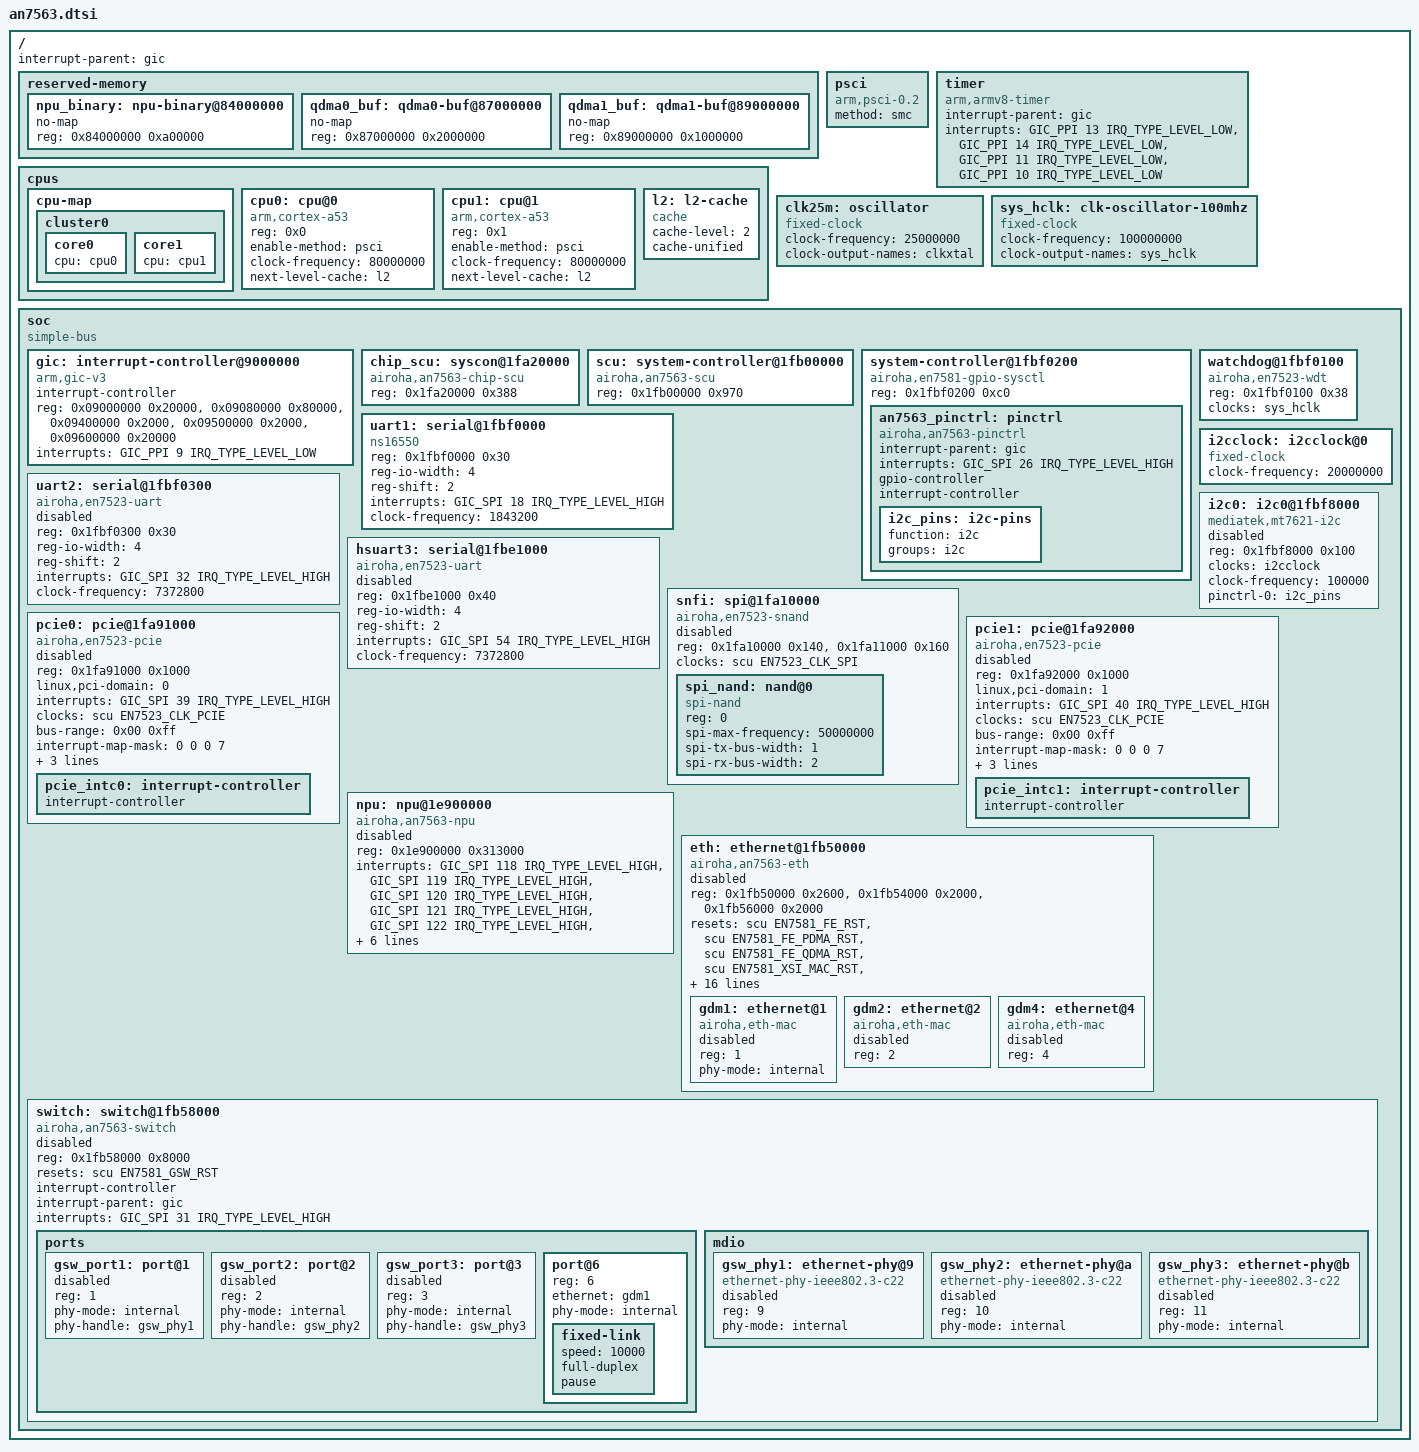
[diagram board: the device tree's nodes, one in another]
// SPDX-License-Identifier: (GPL-2.0-only OR BSD-2-Clause)
/*
 * Airoha AN7563 / AN7552 SoC dtsi.
 *
 * AN7563 boots a dual Cortex-A53 cluster in 32-bit AArch32 mode, but
 * its chip-SCU and SCU register windows match the EN7581 layout (the
 * IOMUX_1 register sits at chip-SCU offset 0x214, not 0x210 as on
 * EN7523). To share clk-en7523 / reset / pinctrl-airoha driver paths
 * with EN7581, the SCU nodes carry an AN7563-specific compatible
 * followed by the "airoha,en7581-{chip-,}scu" fallback compatible.
 */

#include <dt-bindings/interrupt-controller/irq.h>
#include <dt-bindings/interrupt-controller/arm-gic.h>
#include <dt-bindings/clock/en7523-clk.h>
#include <dt-bindings/reset/airoha,en7581-reset.h>
#include <dt-bindings/leds/common.h>

/ {
	interrupt-parent = <&gic>;
	#address-cells = <1>;
	#size-cells = <1>;

	/*
	 * TODO: offsets/sizes below follow the AN7581 pattern and are NOT
	 * yet confirmed against a live BE5000 (no /proc/iomem dump for
	 * this region available at time of writing). Verify before
	 * upstreaming.
	 */
	reserved-memory {
		#address-cells = <1>;
		#size-cells = <1>;
		ranges;

		npu_binary: npu-binary@84000000 {
			no-map;
			reg = <0x84000000 0xa00000>;
		};

		qdma0_buf: qdma0-buf@87000000 {
			no-map;
			reg = <0x87000000 0x2000000>;
		};

		qdma1_buf: qdma1-buf@89000000 {
			no-map;
			reg = <0x89000000 0x1000000>;
		};
	};

	psci {
		compatible = "arm,psci-0.2";
		method = "smc";
	};

	cpus {
		#address-cells = <1>;
		#size-cells = <0>;

		cpu-map {
			cluster0 {
				core0 {
					cpu = <&cpu0>;
				};

				core1 {
					cpu = <&cpu1>;
				};
			};
		};

		cpu0: cpu@0 {
			device_type = "cpu";
			compatible = "arm,cortex-a53";
			reg = <0x0>;
			enable-method = "psci";
			clock-frequency = <80000000>;
			next-level-cache = <&l2>;
		};

		cpu1: cpu@1 {
			device_type = "cpu";
			compatible = "arm,cortex-a53";
			reg = <0x1>;
			enable-method = "psci";
			clock-frequency = <80000000>;
			next-level-cache = <&l2>;
		};

		l2: l2-cache {
			compatible = "cache";
			cache-level = <2>;
			cache-unified;
		};
	};

	timer {
		compatible = "arm,armv8-timer";
		interrupt-parent = <&gic>;
		interrupts = <GIC_PPI 13 IRQ_TYPE_LEVEL_LOW>,
			     <GIC_PPI 14 IRQ_TYPE_LEVEL_LOW>,
			     <GIC_PPI 11 IRQ_TYPE_LEVEL_LOW>,
			     <GIC_PPI 10 IRQ_TYPE_LEVEL_LOW>;
	};

	clk25m: oscillator {
		compatible = "fixed-clock";
		#clock-cells = <0>;
		clock-frequency = <25000000>;
		clock-output-names = "clkxtal";
	};

	sys_hclk: clk-oscillator-100mhz {
		compatible = "fixed-clock";
		#clock-cells = <0>;
		clock-frequency = <100000000>;
		clock-output-names = "sys_hclk";
	};

	soc {
		compatible = "simple-bus";
		#address-cells = <1>;
		#size-cells = <1>;
		ranges;

		gic: interrupt-controller@9000000 {
			compatible = "arm,gic-v3";
			interrupt-controller;
			#interrupt-cells = <3>;
			#address-cells = <1>;
			#size-cells = <1>;
			reg = <0x09000000 0x20000>,
			      <0x09080000 0x80000>,
			      <0x09400000 0x2000>,
			      <0x09500000 0x2000>,
			      <0x09600000 0x20000>;
			interrupts = <GIC_PPI 9 IRQ_TYPE_LEVEL_LOW>;
		};

		chip_scu: syscon@1fa20000 {
			compatible = "airoha,an7563-chip-scu",
				     "airoha,en7581-chip-scu", "syscon";
			reg = <0x1fa20000 0x388>;
		};

		scu: system-controller@1fb00000 {
			compatible = "airoha,an7563-scu",
				     "airoha,en7581-scu", "syscon";
			reg = <0x1fb00000 0x970>;

			#clock-cells = <1>;
			#reset-cells = <1>;
		};

		system-controller@1fbf0200 {
			compatible = "airoha,en7581-gpio-sysctl", "syscon",
				     "simple-mfd";
			reg = <0x1fbf0200 0xc0>;

			/*
			 * Without the en7581-pinctrl fallback, the real
			 * pinctrl-airoha kernel driver (which only knows
			 * "airoha,en7581-pinctrl" in its of_device_id
			 * table) never binds to this node at all - no GPIO
			 * controller gets registered, and anything that
			 * references &an7563_pinctrl (e.g. gpio-keys) is
			 * stuck forever in EPROBE_DEFER (-517), confirmed
			 * on real hardware.
			 */
			an7563_pinctrl: pinctrl {
				compatible = "airoha,an7563-pinctrl",
					     "airoha,en7581-pinctrl";

				interrupt-parent = <&gic>;
				interrupts = <GIC_SPI 26 IRQ_TYPE_LEVEL_HIGH>;

				gpio-controller;
				#gpio-cells = <2>;

				interrupt-controller;
				#interrupt-cells = <2>;

				i2c_pins: i2c-pins {
					function = "i2c";
					groups = "i2c";
				};
			};
		};

		uart1: serial@1fbf0000 {
			compatible = "ns16550";
			reg = <0x1fbf0000 0x30>;
			reg-io-width = <4>;
			reg-shift = <2>;
			interrupts = <GIC_SPI 18 IRQ_TYPE_LEVEL_HIGH>;
			clock-frequency = <1843200>;
		};

		watchdog@1fbf0100 {
			compatible = "airoha,en7523-wdt";
			reg = <0x1fbf0100 0x38>;

			clocks = <&sys_hclk>;
			clock-names = "bus";
		};

		uart2: serial@1fbf0300 {
			compatible = "airoha,en7523-uart";
			reg = <0x1fbf0300 0x30>;
			reg-io-width = <4>;
			reg-shift = <2>;
			interrupts = <GIC_SPI 32 IRQ_TYPE_LEVEL_HIGH>;
			clock-frequency = <7372800>;

			status = "disabled";
		};

		hsuart3: serial@1fbe1000 {
			compatible = "airoha,en7523-uart";
			reg = <0x1fbe1000 0x40>;
			reg-io-width = <4>;
			reg-shift = <2>;
			interrupts = <GIC_SPI 54 IRQ_TYPE_LEVEL_HIGH>;
			clock-frequency = <7372800>;

			status = "disabled";
		};

		i2cclock: i2cclock@0 {
			#clock-cells = <0>;
			compatible = "fixed-clock";

			/* 20 MHz */
			clock-frequency = <20000000>;
		};

		i2c0: i2c0@1fbf8000 {
			compatible = "mediatek,mt7621-i2c";
			reg = <0x1fbf8000 0x100>;

			clocks = <&i2cclock>;

			/* 100 kHz */
			clock-frequency = <100000>;
			#address-cells = <1>;
			#size-cells = <0>;

			pinctrl-names = "default";
			pinctrl-0 = <&i2c_pins>;

			status = "disabled";
		};

		snfi: spi@1fa10000 {
			compatible = "airoha,en7523-snand", "airoha,en7581-snand";
			reg = <0x1fa10000 0x140>,
			      <0x1fa11000 0x160>;

			clocks = <&scu EN7523_CLK_SPI>;
			clock-names = "spi";

			#address-cells = <1>;
			#size-cells = <0>;

			status = "disabled";

			spi_nand: nand@0 {
				compatible = "spi-nand";
				reg = <0>;
				spi-max-frequency = <50000000>;
				spi-tx-bus-width = <1>;
				spi-rx-bus-width = <2>;
			};
		};

		pcie0: pcie@1fa91000 {
			compatible = "airoha,en7523-pcie", "mediatek,mt7622-pcie";
			device_type = "pci";
			reg = <0x1fa91000 0x1000>;
			reg-names = "port0";
			linux,pci-domain = <0>;
			#address-cells = <3>;
			#size-cells = <2>;
			interrupts = <GIC_SPI 39 IRQ_TYPE_LEVEL_HIGH>;
			interrupt-names = "pcie_irq";
			clocks = <&scu EN7523_CLK_PCIE>;
			clock-names = "sys_ck0";
			bus-range = <0x00 0xff>;
			ranges = <0x82000000 0 0x20000000 0x20000000 0 0x2000000>;

			status = "disabled";

			#interrupt-cells = <1>;
			interrupt-map-mask = <0 0 0 7>;
			interrupt-map = <0 0 0 1 &pcie_intc0 0>,
					<0 0 0 2 &pcie_intc0 1>,
					<0 0 0 3 &pcie_intc0 2>,
					<0 0 0 4 &pcie_intc0 3>;

			pcie_intc0: interrupt-controller {
				interrupt-controller;
				#address-cells = <0>;
				#interrupt-cells = <1>;
			};
		};

		pcie1: pcie@1fa92000 {
			compatible = "airoha,en7523-pcie", "mediatek,mt7622-pcie";
			device_type = "pci";
			reg = <0x1fa92000 0x1000>;
			reg-names = "port1";
			linux,pci-domain = <1>;
			#address-cells = <3>;
			#size-cells = <2>;
			interrupts = <GIC_SPI 40 IRQ_TYPE_LEVEL_HIGH>;
			interrupt-names = "pcie_irq";
			clocks = <&scu EN7523_CLK_PCIE>;
			clock-names = "sys_ck1";
			bus-range = <0x00 0xff>;
			ranges = <0x82000000 0 0x22000000 0x22000000 0 0x2000000>;

			status = "disabled";

			#interrupt-cells = <1>;
			interrupt-map-mask = <0 0 0 7>;
			interrupt-map = <0 0 0 1 &pcie_intc1 0>,
					<0 0 0 2 &pcie_intc1 1>,
					<0 0 0 3 &pcie_intc1 2>,
					<0 0 0 4 &pcie_intc1 3>;

			pcie_intc1: interrupt-controller {
				interrupt-controller;
				#address-cells = <0>;
				#interrupt-cells = <1>;
			};
		};

		/*
		 * reg/interrupts confirmed against the stock BE5000
		 * npu@1e800000 dtb dump (econet,ecnt-npu).
		 */
		/*
		 * reg CONFIRMED WRONG in the previous round and fixed here
		 * by reading the actual airoha_npu.c driver source
		 * (drivers/net/ethernet/airoha/airoha_npu.c upstream):
		 * airoha_npu_probe() does
		 *   base = devm_platform_ioremap_resource(pdev, 0);
		 * i.e. maps reg[0] as the real NPU register block, then
		 * writes to offsets up to ~0x310184 (NPU_TIMER_BASE_ADDR
		 * area) through it. The old reg[0]=<0x1e800000 0x60000>
		 * (taken from the vendor stock dtb, which uses a different,
		 * vendor-specific driver) is both the wrong base address
		 * AND far too small (0x60000) for those offsets - a
		 * confirmed out-of-bounds ioremap access, likely the real
		 * cause of the "strcmp/__of_device_is_compatible" crashes
		 * seen across earlier test rounds (memory corruption from
		 * writes past the mapped region, manifesting elsewhere).
		 * Single region now, matching upstream an7581.dtsi exactly.
		 *
		 * NOTE: "airoha,an7563-npu" is NOT in the driver's
		 * of_device_id table (only en7581-npu/an7583-npu are) - it
		 * matches via the en7581-npu fallback compatible, which
		 * also means it uses en7581's firmware filenames by
		 * default (en7581_npu_rv32.bin/en7581_npu_data.bin), NOT
		 * the MT7996-variant files. an7563.mk currently references
		 * airoha-en7581-mt7996-npu-firmware (MT7996-variant
		 * filenames) - this mismatch needs resolving (either switch
		 * the package to the plain en7581 variant, or add an
		 * explicit "firmware-name" property here to request the
		 * MT7996 filenames) before NPU firmware will actually load.
		 *
		 * ALSO NOTE: interrupts count (9) is fewer than an7581.dtsi's
		 * 15 (1 mbox + 4 core-wdt + 10 wlan queues) - the driver's
		 * probe loop indexes a fixed number of core/wlan irqs
		 * (NPU_NUM_CORES / ARRAY_SIZE(npu->irqs), shared constants
		 * across the whole driver, not SoC-specific). If AN7563
		 * really has fewer, platform_get_irq() will fail cleanly
		 * with -ENXIO once the reg fix above is in place - watch
		 * for that in the next boot log rather than another silent
		 * crash.
		 */
		npu: npu@1e900000 {
			compatible = "airoha,an7563-npu", "airoha,en7581-npu";
			reg = <0x1e900000 0x313000>;
			interrupts = <GIC_SPI 118 IRQ_TYPE_LEVEL_HIGH>,
				     <GIC_SPI 119 IRQ_TYPE_LEVEL_HIGH>,
				     <GIC_SPI 120 IRQ_TYPE_LEVEL_HIGH>,
				     <GIC_SPI 121 IRQ_TYPE_LEVEL_HIGH>,
				     <GIC_SPI 122 IRQ_TYPE_LEVEL_HIGH>,
				     <GIC_SPI 123 IRQ_TYPE_LEVEL_HIGH>,
				     <GIC_SPI 125 IRQ_TYPE_LEVEL_HIGH>,
				     <GIC_SPI 134 IRQ_TYPE_LEVEL_HIGH>,
				     <GIC_SPI 135 IRQ_TYPE_LEVEL_HIGH>;
			memory-region = <&npu_binary>;
			memory-region-names = "binary";

			status = "disabled";
		};

		/*
		 * fe/qdma reg confirmed against stock BE5000 dtb
		 * (frame_engine@1fb50000: 0x1fb50000/0x2600,
		 * 0x1fb54000/0x4000 combined qdma0+qdma1, matches the
		 * 0x1fb54000/0x2000 + 0x1fb56000/0x2000 split used here).
		 * interrupts list order/values also confirmed 1:1 against
		 * the stock dtb's frame_engine@1fb50000 interrupts property
		 * (37,55,56,57,38,58,59,60,49,64 decimal).
		 * resets trimmed to the 6 lines present in the U-Boot
		 * 310-...-AN7563-SoC.patch eth node (no xsi-mac/xfp-mac,
		 * AN7563 has no PON/10G uplink unlike AN7581).
		 */
		/*
		 * IMPORTANT: reverted back to "airoha,en7581-eth" -
		 * "airoha,en7523-eth" (from xinyooo's an7563.dtsi) turned
		 * out to have NO matching driver in this kernel build at
		 * all: device status was "okay" but nothing in dmesg ever
		 * mentioned airoha_eth/switch, and no driver was bound
		 * (confirmed on real hardware). en7523 is a separate 32-bit
		 * ARM subtarget in mainline OpenWrt with its own legacy
		 * driver stack; our AN7563 build uses the same 64-bit
		 * "airoha" target/kernel tree as AN7581, whose
		 * drivers/net/ethernet/airoha/airoha_eth.c only knows
		 * "airoha,en7581-eth" (confirmed working - this is what
		 * hung on the NPU mbox handshake in earlier rounds).
		 *
		 * This round tests an UNTESTED variable: en7581-eth kept,
		 * but the "airoha,npu = <&npu>;" phandle removed entirely.
		 * If airoha_ppe_init()/NPU handshake in the driver is only
		 * triggered when that phandle resolves to a valid device
		 * (rather than unconditionally), this should let eth probe
		 * complete without ever touching NPU/mbox.
		 */
		eth: ethernet@1fb50000 {
			compatible = "airoha,an7563-eth", "airoha,en7581-eth";
			reg = <0x1fb50000 0x2600>,
			      <0x1fb54000 0x2000>,
			      <0x1fb56000 0x2000>;
			reg-names = "fe", "qdma0", "qdma1";

			resets = <&scu EN7581_FE_RST>,
				 <&scu EN7581_FE_PDMA_RST>,
				 <&scu EN7581_FE_QDMA_RST>,
				 <&scu EN7581_XSI_MAC_RST>,
				 <&scu EN7581_DUAL_HSI0_MAC_RST>,
				 <&scu EN7581_DUAL_HSI1_MAC_RST>,
				 <&scu EN7581_HSI_MAC_RST>,
				 <&scu EN7581_XFP_MAC_RST>;
			reset-names = "fe", "pdma", "qdma", "xsi-mac",
				      "hsi0-mac", "hsi1-mac", "hsi-mac",
				      "xfp-mac";

			interrupts = <GIC_SPI 37 IRQ_TYPE_LEVEL_HIGH>,
				     <GIC_SPI 55 IRQ_TYPE_LEVEL_HIGH>,
				     <GIC_SPI 56 IRQ_TYPE_LEVEL_HIGH>,
				     <GIC_SPI 57 IRQ_TYPE_LEVEL_HIGH>,
				     <GIC_SPI 38 IRQ_TYPE_LEVEL_HIGH>,
				     <GIC_SPI 58 IRQ_TYPE_LEVEL_HIGH>,
				     <GIC_SPI 59 IRQ_TYPE_LEVEL_HIGH>,
				     <GIC_SPI 60 IRQ_TYPE_LEVEL_HIGH>,
				     <GIC_SPI 49 IRQ_TYPE_LEVEL_HIGH>,
				     <GIC_SPI 64 IRQ_TYPE_LEVEL_HIGH>;

			memory-region = <&qdma0_buf>, <&qdma1_buf>;
			memory-region-names = "qdma0-buf", "qdma1-buf";

			/* airoha,npu intentionally NOT set - see comment above */

			status = "disabled";

			#address-cells = <1>;
			#size-cells = <0>;

			/*
			 * gdm1 is used as the switch's conduit port (see
			 * port@6 inside switch/ports below, which links via
			 * "ethernet = <&gdm1>"). gdm2 is enabled at board
			 * level for the EN8811H 2.5G WAN PHY. gdm4 stays
			 * unused/disabled.
			 */
			gdm1: ethernet@1 {
				compatible = "airoha,eth-mac";
				reg = <1>;
				phy-mode = "internal";
				status = "disabled";
			};

			gdm2: ethernet@2 {
				compatible = "airoha,eth-mac";
				reg = <2>;
				status = "disabled";
			};

			gdm4: ethernet@4 {
				compatible = "airoha,eth-mac";
				reg = <4>;
				status = "disabled";
			};
		};

		/*
		 * switch reg confirmed against stock BE5000 dtb
		 * (frame_engine@1fb50000 third reg entry: 0x1fb58000/0x8000).
		 * ports/mdio structure adapted from an7581.dtsi, trimmed to
		 * 3 internal PHYs (BE5000 has 3x built-in 1G LAN, no 4th
		 * internal port). gsw_phy1/2/3 MDIO addresses 9/10/11
		 * confirmed against a live BE5000's own dmesg
		 * (ephy_addr = 9/10/11 for port_num 0/1/2).
		 */
		switch: switch@1fb58000 {
			compatible = "airoha,an7563-switch",
				     "airoha,en7523-switch",
				     "airoha,en7581-switch";
			reg = <0x1fb58000 0x8000>;
			resets = <&scu EN7581_GSW_RST>;

			/*
			 * Confirmed against upstream an7581.dtsi - the
			 * switch registers itself as an interrupt-controller
			 * for per-port link IRQs. Missing this was likely
			 * part of why enabling switch alone never actually
			 * produced usable interfaces.
			 */
			interrupt-controller;
			#interrupt-cells = <1>;
			interrupt-parent = <&gic>;
			interrupts = <GIC_SPI 31 IRQ_TYPE_LEVEL_HIGH>;

			status = "disabled";

			#address-cells = <1>;
			#size-cells = <1>;

			ports {
				#address-cells = <1>;
				#size-cells = <0>;

				gsw_port1: port@1 {
					reg = <1>;
					phy-mode = "internal";
					phy-handle = <&gsw_phy1>;
					status = "disabled";
				};

				gsw_port2: port@2 {
					reg = <2>;
					phy-mode = "internal";
					phy-handle = <&gsw_phy2>;
					status = "disabled";
				};

				gsw_port3: port@3 {
					reg = <3>;
					phy-mode = "internal";
					phy-handle = <&gsw_phy3>;
					status = "disabled";
				};

				/*
				 * CPU/conduit port linking the switch fabric
				 * to gdm1. Without this, gsw_port1/2/3 have
				 * no path out to the network stack at all -
				 * confirmed missing from our earlier attempts
				 * by comparing against upstream an7581.dtsi.
				 */
				port@6 {
					reg = <6>;
					ethernet = <&gdm1>;
					phy-mode = "internal";

					fixed-link {
						speed = <10000>;
						full-duplex;
						pause;
					};
				};
			};

			mdio: mdio {
				#address-cells = <1>;
				#size-cells = <0>;

				gsw_phy1: ethernet-phy@9 {
					compatible = "ethernet-phy-ieee802.3-c22";
					reg = <9>;
					phy-mode = "internal";
					status = "disabled";
				};

				gsw_phy2: ethernet-phy@a {
					compatible = "ethernet-phy-ieee802.3-c22";
					reg = <10>;
					phy-mode = "internal";
					status = "disabled";
				};

				gsw_phy3: ethernet-phy@b {
					compatible = "ethernet-phy-ieee802.3-c22";
					reg = <11>;
					phy-mode = "internal";
					status = "disabled";
				};
			};
		};
	};
};
